# ESP32-S2 register map
Vendor: ESPRESSIF SYSTEMS (SHANGHAI) CO., LTD.; Series: ESP32 S-Series; File version: 20
CPU: Xtensa LX7 r0p0, little endian, no MPU, no FPU, 0 interrupt priority bits
Address unit: 32 bits
Registers are 32-bit, read-write, reset 0x0 unless marked. A register's access mark holds for its fields unless they carry their own. Offsets are from the block's base; [hi:lo] are bit positions.

## I2S0 — I2S (Inter-IC Sound) Controller 0
Base 0x3F40F000
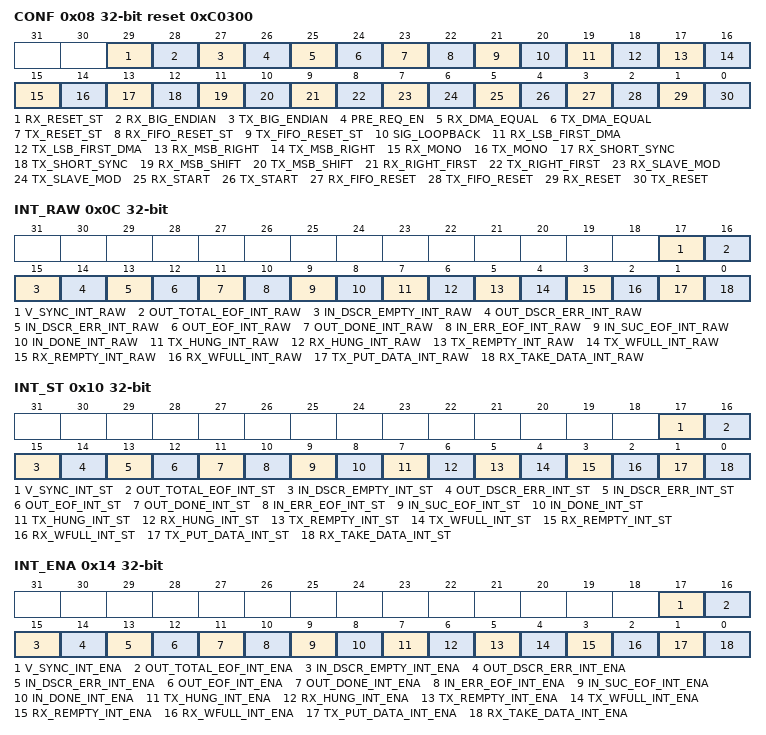
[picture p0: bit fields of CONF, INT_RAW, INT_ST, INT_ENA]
0x08 CONF access per field reset 0xC0300 — I2S configuration register
  [29] RX_RESET_ST ro — I2S RX reset status. 1: I2S_RX_RESET is not completed. 0: I2S_RX_RESET is completed.
  [28] RX_BIG_ENDIAN rw — I2S RX byte endianness.
  [27] TX_BIG_ENDIAN rw — I2S TX byte endianness.
  [26] PRE_REQ_EN rw — Set this bit to enable I2S to prepare data earlier.
  [25] RX_DMA_EQUAL rw — 1: Data in left channel is equal to data in right channel. 0: Data in left channel is not equal to data in right channel.
  [24] TX_DMA_EQUAL rw — 1: Data in left channel is equal to data in right channel. 0: Data in left channel is not equal to data in right channel.
  [23] TX_RESET_ST ro — I2S TX reset status. 1: I2S_TX_RESET is not completed. 0: I2S_TX_RESET is completed.
  [22] RX_FIFO_RESET_ST ro — I2S RX FIFO reset status. 1: I2S_RX_FIFO_RESET is not completed. 0: I2S_RX_FIFO_RESET is completed.
  [21] TX_FIFO_RESET_ST ro — I2S TX FIFO reset status. 1: I2S_TX_FIFO_RESET is not completed. 0: I2S_TX_FIFO_RESET is completed.
  [20] SIG_LOOPBACK rw — Enable signal loopback mode with transmitter module and receiver module sharing the same WS and BCK signals.
  [19] RX_LSB_FIRST_DMA rw — 1:the data in DMA/APB transform from low bits. 0:the data from DMA/APB transform from high bits.
  [18] TX_LSB_FIRST_DMA rw — 1:the data in DMA/APB transform from low bits. 0:the data from DMA/APB transform from high bits.
  [17] RX_MSB_RIGHT rw — Set this bit to place right channel data at the MSB in RX FIFO.
  [16] TX_MSB_RIGHT rw — Set this bit to place right channel data at the MSB in TX FIFO.
  [15] RX_MONO rw — Set this bit to enable receiver in mono mode.
  [14] TX_MONO rw — Set this bit to enable transmitter in mono mode.
  [13] RX_SHORT_SYNC rw — Set this bit to enable receiver in PCM standard mode.
  [12] TX_SHORT_SYNC rw — Set this bit to enable transmitter in PCM standard mode.
  [11] RX_MSB_SHIFT rw — Set this bit to enable receiver in Phillips standard mode.
  [10] TX_MSB_SHIFT rw — Set this bit to enable transmitter in Phillips standard mode.
  [9] RX_RIGHT_FIRST rw — Set this bit to receive right channel data first.
  [8] TX_RIGHT_FIRST rw — Set this bit to transmit right channel data first.
  [7] RX_SLAVE_MOD rw — Set this bit to enable slave receiver mode.
  [6] TX_SLAVE_MOD rw — Set this bit to enable slave transmitter mode.
  [5] RX_START rw — Set this bit to start receiving data.
  [4] TX_START rw — Set this bit to start transmitting data.
  [3] RX_FIFO_RESET wo — Set this bit to reset RX FIFO.
  [2] TX_FIFO_RESET wo — Set this bit to reset TX FIFO.
  [1] RX_RESET wo — Set this bit to reset receiver.
  [0] TX_RESET wo — Set this bit to reset transmitter.
0x0C INT_RAW ro — Raw interrupt status
  [17] V_SYNC_INT_RAW — The raw interrupt status bit for I2S_V_SYNC_INT interrupt.
  [16] OUT_TOTAL_EOF_INT_RAW — The raw interrupt status bit for I2S_OUT_TOTAL_EOF_INT interrupt.
  [15] IN_DSCR_EMPTY_INT_RAW — The raw interrupt status bit for I2S_IN_DSCR_EMPTY_INT interrupt.
  [14] OUT_DSCR_ERR_INT_RAW — The raw interrupt status bit for I2S_OUT_DSCR_ERR_INT interrupt.
  [13] IN_DSCR_ERR_INT_RAW — The raw interrupt status bit for I2S_IN_DSCR_ERR_INT interrupt.
  [12] OUT_EOF_INT_RAW — The raw interrupt status bit for I2S_OUT_EOF_INT interrupt.
  [11] OUT_DONE_INT_RAW — The raw interrupt status bit for I2S_OUT_DONE_INT interrupt.
  [10] IN_ERR_EOF_INT_RAW — Reserved.
  [9] IN_SUC_EOF_INT_RAW — The raw interrupt status bit for I2S_IN_SUC_EOF_INT interrupt.
  [8] IN_DONE_INT_RAW — The raw interrupt status bit for I2S_IN_DONE_INT interrupt.
  [7] TX_HUNG_INT_RAW — The raw interrupt status bit for I2S_TX_HUNG_INT interrupt.
  [6] RX_HUNG_INT_RAW — The raw interrupt status bit for I2S_RX_HUNG_INT interrupt.
  [5] TX_REMPTY_INT_RAW — The raw interrupt status bit for I2S_TX_REMPTY_INT interrupt.
  [4] TX_WFULL_INT_RAW — The raw interrupt status bit for I2S_TX_WFULL_INT interrupt.
  [3] RX_REMPTY_INT_RAW — The raw interrupt status bit for I2S_RX_REMPTY_INT interrupt.
  [2] RX_WFULL_INT_RAW — The raw interrupt status bit for I2S_RX_WFULL_INT interrupt.
  [1] TX_PUT_DATA_INT_RAW — The raw interrupt status bit for I2S_TX_PUT_DATA_INT interrupt.
  [0] RX_TAKE_DATA_INT_RAW — The raw interrupt status bit for I2S_RX_TAKE_DATA_INT interrupt.
0x10 INT_ST ro — Masked interrupt status
  [17] V_SYNC_INT_ST — The masked interrupt status bit for I2S_V_SYNC_INT interrupt.
  [16] OUT_TOTAL_EOF_INT_ST — The masked interrupt status bit for I2S_OUT_TOTAL_EOF_INT interrupt.
  [15] IN_DSCR_EMPTY_INT_ST — The masked interrupt status bit for I2S_IN_DSCR_EMPTY_INT interrupt.
  [14] OUT_DSCR_ERR_INT_ST — The masked interrupt status bit for I2S_OUT_DSCR_ERR_INT interrupt.
  [13] IN_DSCR_ERR_INT_ST — The masked interrupt status bit for I2S_IN_DSCR_ERR_INT interrupt.
  [12] OUT_EOF_INT_ST — The masked interrupt status bit for I2S_OUT_EOF_INT interrupt.
  [11] OUT_DONE_INT_ST — The masked interrupt status bit for I2S_OUT_DONE_INT interrupt.
  [10] IN_ERR_EOF_INT_ST — Reserved.
  [9] IN_SUC_EOF_INT_ST — The masked interrupt status bit for I2S_IN_SUC_EOF_INT interrupt.
  [8] IN_DONE_INT_ST — The masked interrupt status bit for I2S_IN_DONE_INT interrupt.
  [7] TX_HUNG_INT_ST — The masked interrupt status bit for I2S_TX_HUNG_INT interrupt.
  [6] RX_HUNG_INT_ST — The masked interrupt status bit for I2S_RX_HUNG_INT interrupt.
  [5] TX_REMPTY_INT_ST — The masked interrupt status bit for I2S_TX_REMPTY_INT interrupt.
  [4] TX_WFULL_INT_ST — The masked interrupt status bit for I2S_TX_WFULL_INT interrupt.
  [3] RX_REMPTY_INT_ST — The masked interrupt status bit for I2S_RX_REMPTY_INT interrupt.
  [2] RX_WFULL_INT_ST — The masked interrupt status bit for I2S_RX_WFULL_INT interrupt.
  [1] TX_PUT_DATA_INT_ST — The masked interrupt status bit for I2S_TX_PUT_DATA_INT interrupt.
  [0] RX_TAKE_DATA_INT_ST — The masked interrupt status bit for I2S_RX_TAKE_DATA_INT interrupt.
0x14 INT_ENA — Interrupt enable bits
  [17] V_SYNC_INT_ENA — The interrupt enable bit for I2S_V_SYNC_INT interrupt.
  [16] OUT_TOTAL_EOF_INT_ENA — The interrupt enable bit for I2S_OUT_TOTAL_EOF_INT interrupt.
  [15] IN_DSCR_EMPTY_INT_ENA — The interrupt enable bit for I2S_IN_DSCR_EMPTY_INT interrupt.
  [14] OUT_DSCR_ERR_INT_ENA — The interrupt enable bit for I2S_OUT_DSCR_ERR_INT interrupt.
  [13] IN_DSCR_ERR_INT_ENA — The interrupt enable bit for I2S_IN_DSCR_ERR_INT interrupt.
  [12] OUT_EOF_INT_ENA — The interrupt enable bit for I2S_OUT_EOF_INT interrupt.
  [11] OUT_DONE_INT_ENA — The interrupt enable bit for I2S_OUT_DONE_INT interrupt.
  [10] IN_ERR_EOF_INT_ENA — Reserved.
  [9] IN_SUC_EOF_INT_ENA — The interrupt enable bit for I2S_IN_SUC_EOF_INT interrupt.
  [8] IN_DONE_INT_ENA — The interrupt enable bit for I2S_IN_DONE_INT interrupt.
  [7] TX_HUNG_INT_ENA — The interrupt enable bit for I2S_TX_HUNG_INT interrupt.
  [6] RX_HUNG_INT_ENA — The interrupt enable bit for I2S_RX_HUNG_INT interrupt.
  [5] TX_REMPTY_INT_ENA — The interrupt enable bit for I2S_TX_REMPTY_INT interrupt.
  [4] TX_WFULL_INT_ENA — The interrupt enable bit for I2S_TX_WFULL_INT interrupt.
  [3] RX_REMPTY_INT_ENA — The interrupt enable bit for I2S_RX_REMPTY_INT interrupt.
  [2] RX_WFULL_INT_ENA — The interrupt enable bit for I2S_RX_WFULL_INT interrupt.
  [1] TX_PUT_DATA_INT_ENA — The interrupt enable bit for I2S_TX_PUT_DATA_INT interrupt.
  [0] RX_TAKE_DATA_INT_ENA — The interrupt enable bit for I2S_RX_TAKE_DATA_INT interrupt.
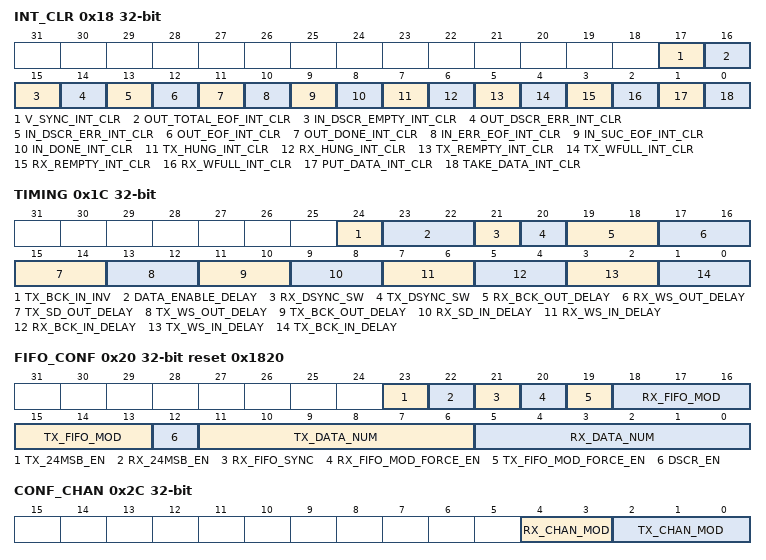
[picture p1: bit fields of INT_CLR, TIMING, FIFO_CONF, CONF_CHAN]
0x18 INT_CLR wo — Interrupt clear bits
  [17] V_SYNC_INT_CLR — Set this bit to clear I2S_V_SYNC_INT interrupt.
  [16] OUT_TOTAL_EOF_INT_CLR — Set this bit to clear I2S_OUT_TOTAL_EOF_INT interrupt.
  [15] IN_DSCR_EMPTY_INT_CLR — Set this bit to clear I2S_IN_DSCR_EMPTY_INT interrupt.
  [14] OUT_DSCR_ERR_INT_CLR — Set this bit to clear I2S_OUT_DSCR_ERR_INT interrupt.
  [13] IN_DSCR_ERR_INT_CLR — Set this bit to clear I2S_IN_DSCR_ERR_INT interrupt.
  [12] OUT_EOF_INT_CLR — Set this bit to clear I2S_OUT_EOF_INT interrupt.
  [11] OUT_DONE_INT_CLR — Set this bit to clear I2S_OUT_DONE_INT interrupt.
  [10] IN_ERR_EOF_INT_CLR — Reserved.
  [9] IN_SUC_EOF_INT_CLR — Set this bit to clear I2S_IN_SUC_EOF_INT interrupt.
  [8] IN_DONE_INT_CLR — Set this bit to clear I2S_IN_DONE_INT interrupt.
  [7] TX_HUNG_INT_CLR — Set this bit to clear I2S_TX_HUNG_INT interrupt.
  [6] RX_HUNG_INT_CLR — Set this bit to clear I2S_RX_HUNG_INT interrupt.
  [5] TX_REMPTY_INT_CLR — Set this bit to clear I2S_TX_REMPTY_INT interrupt.
  [4] TX_WFULL_INT_CLR — Set this bit to clear I2S_TX_WFULL_INT interrupt.
  [3] RX_REMPTY_INT_CLR — Set this bit to clear I2S_RX_REMPTY_INT interrupt.
  [2] RX_WFULL_INT_CLR — Set this bit to clear I2S_RX_WFULL_INT interrupt.
  [1] PUT_DATA_INT_CLR — Set this bit to clear I2S_TX_PUT_DATA_INT interrupt.
  [0] TAKE_DATA_INT_CLR — Set this bit to clear I2S_RX_TAKE_DATA_INT interrupt.
0x1C TIMING — I2S timing register
  [24] TX_BCK_IN_INV — Set this bit to invert BCK signal input to the slave transmitter.
  [23:22] DATA_ENABLE_DELAY — Number of delay cycles for data valid flag based on I2S0_CLK. 0: delayed by 1.5 cycles. 1: delayed by 2.5 cycles. 2: delayed by 3.5 cycles. 3: delayed by 4.5 cycles.
  [21] RX_DSYNC_SW — Set this bit to synchronize signals into the receiver by two flip-flop synchronizer. 0: the signals will be clocked by rising clock edge firstly, then clocked by falling clock edge. 1: the signals will be clocked by falling clock edge firstly, then clocked by rising clock edge.
  [20] TX_DSYNC_SW — Set this bit to synchronize signals into the transmitter by two flip-flop synchronizer. 0: the signals will be firstly clocked by rising clock edge , then clocked by falling clock edge. 1: the signals will be firstly clocked by falling clock edge, then clocked by rising clock edge.
  [19:18] RX_BCK_OUT_DELAY — Number of delay cycles for BCK signal out of the receiver based on I2S0_CLK. 0: delayed by 0 cycle. 1: delayed by 1 cycle. 2: delayed by 2 cycles. 3: delayed by 3 cycles.
  [17:16] RX_WS_OUT_DELAY — Number of delay cycles for WS signal out of the receiver based on I2S0_CLK. 0: delayed by 0 cycle. 1: delayed by 1 cycle. 2: delayed by 2 cycles. 3: delayed by 3 cycles.
  [15:14] TX_SD_OUT_DELAY — Number of delay cycles for SD signal out of the transmitter based on I2S0_CLK. 0: delayed by 0 cycle. 1: delayed by 1 cycle. 2: delayed by 2 cycles. 3: delayed by 3 cycles.
  [13:12] TX_WS_OUT_DELAY — Number of delay cycles for WS signal out of the transmitter based on I2S0_CLK. 0: delayed by 0 cycle. 1: delayed by 1 cycle. 2: delayed by 2 cycles. 3: delayed by 3 cycles.
  [11:10] TX_BCK_OUT_DELAY — Number of delay cycles for BCK signal out of the transmitter based on I2S0_CLK. 0: delayed by 0 cycle. 1: delayed by 1 cycle. 2: delayed by 2 cycles. 3: delayed by 3 cycles.
  [9:8] RX_SD_IN_DELAY — Number of delay cycles for SD signal into the receiver based on I2S0_CLK. 0: delayed by 1.5 cycles. 1: delayed by 2.5 cycles. 2: delayed by 3.5 cycles. 3: delayed by 4.5 cycles.
  [7:6] RX_WS_IN_DELAY — Number of delay cycles for WS signal into the receiver based on I2S0_CLK. 0: delayed by 1.5 cycles. 1: delayed by 2.5 cycles. 2: delayed by 3.5 cycles. 3: delayed by 4.5 cycles.
  [5:4] RX_BCK_IN_DELAY — Number of delay cycles for BCK signal into the receiver based on I2S0_CLK. 0: delayed by 1.5 cycles. 1: delayed by 2.5 cycles. 2: delayed by 3.5 cycles. 3: delayed by 4.5 cycles.
  [3:2] TX_WS_IN_DELAY — Number of delay cycles for WS signal into the transmitter based on I2S0_CLK. 0: delayed by 1.5 cycles. 1: delayed by 2.5 cycles. 2: delayed by 3.5 cycles. 3: delayed by 4.5 cycles.
  [1:0] TX_BCK_IN_DELAY — Number of delay cycles for BCK signal into the transmitter based on I2S0_CLK. 0: delayed by 1.5 cycles. 1: delayed by 2.5 cycles. 2: delayed by 3.5 cycles. 3: delayed by 4.5 cycles.
0x20 FIFO_CONF reset 0x1820 — I2S FIFO configuration register
  [23] TX_24MSB_EN — Only useful in tx 24bit mode. 1: the high 24 bits are effective in i2s fifo 0: the low 24 bits are effective in i2s fifo
  [22] RX_24MSB_EN — Only useful in rx 24bit mode. 1: the high 24 bits are effective in i2s fifo 0: the low 24 bits are effective in i2s fifo
  [21] RX_FIFO_SYNC — force write back rx data to memory
  [20] RX_FIFO_MOD_FORCE_EN — The bit should always be set to 1
  [19] TX_FIFO_MOD_FORCE_EN — The bit should always be set to 1
  [18:16] RX_FIFO_MOD — Receiver FIFO mode configuration bits
  [15:13] TX_FIFO_MOD — Transmitter FIFO mode configuration bits
  [12] DSCR_EN — Set this bit to enable I2S DMA mode.
  [11:6] TX_DATA_NUM — I2S_TX_PUT_DATA_INT is triggered when the left and right channel data number in TX FIFO is smaller than the value of I2S_TX_DATA_NUM[5:0]. (TX FIFO is almost empty threshold.)
  [5:0] RX_DATA_NUM — I2S_RX_TAKE_DATA_INT is triggered when the left and right channel data number in RX FIFO is larger than the value of I2S_RX_DATA_NUM[5:0]. (RX FIFO is almost full threshold.)
0x24 RXEOF_NUM reset 0x40 — I2S DMA RX EOF data length
  [31:0] RX_EOF_NUM — The length of data to be received. It will trigger I2S_IN_SUC_EOF_INT.
0x28 CONF_SIGLE_DATA — Constant single channel data
  [31:0] SIGLE_DATA — The right channel or left channel transmits constant value stored in this register according to I2S_TX_CHAN_MOD and I2S_TX_MSB_RIGHT.
0x2C CONF_CHAN — I2S channel configuration register
  [4:3] RX_CHAN_MOD — I2S receiver channel mode configuration bits.
  [2:0] TX_CHAN_MOD — I2S transmitter channel mode configuration bits.
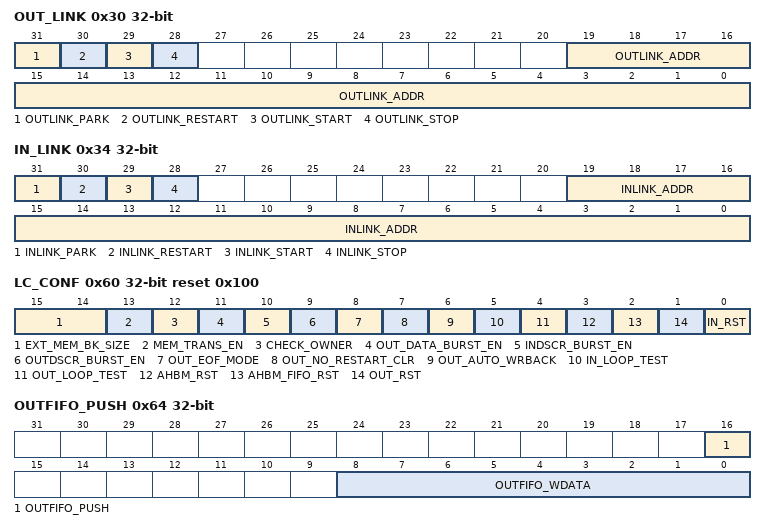
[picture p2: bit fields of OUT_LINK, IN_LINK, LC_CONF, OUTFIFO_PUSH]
0x30 OUT_LINK access per field — I2S DMA TX configuration register
  [31] OUTLINK_PARK ro
  [30] OUTLINK_RESTART rw — Set this bit to restart outlink descriptor.
  [29] OUTLINK_START rw — Set this bit to start outlink descriptor.
  [28] OUTLINK_STOP rw — Set this bit to stop outlink descriptor.
  [19:0] OUTLINK_ADDR rw — The address of first outlink descriptor.
0x34 IN_LINK access per field — I2S DMA RX configuration register
  [31] INLINK_PARK ro
  [30] INLINK_RESTART rw — Set this bit to restart inlink descriptor.
  [29] INLINK_START rw — Set this bit to start inlink descriptor.
  [28] INLINK_STOP rw — Set this bit to stop inlink descriptor.
  [19:0] INLINK_ADDR rw — The address of first inlink descriptor.
0x38 OUT_EOF_DES_ADDR ro — Address of outlink descriptor that produces EOF
  [31:0] OUT_EOF_DES_ADDR — The address of outlink descriptor that produces EOF.
0x3C IN_EOF_DES_ADDR ro — Address of inlink descriptor that produces EOF
  [31:0] IN_SUC_EOF_DES_ADDR — The address of inlink descriptor that produces EOF.
0x40 OUT_EOF_BFR_DES_ADDR ro — Address of buffer relative to the outlink descriptor that produces EOF
  [31:0] OUT_EOF_BFR_DES_ADDR — The address of buffer relative to the outlink descriptor that produces EOF.
0x48 INLINK_DSCR ro — Address of current inlink descriptor
  [31:0] INLINK_DSCR — The address of current inlink descriptor.
0x4C INLINK_DSCR_BF0 ro — Address of next inlink descriptor
  [31:0] INLINK_DSCR_BF0 — The address of next inlink descriptor.
0x50 INLINK_DSCR_BF1 ro — Address of next inlink data buffer
  [31:0] INLINK_DSCR_BF1 — The address of next inlink data buffer.
0x54 OUTLINK_DSCR ro — Address of current outlink descriptor
  [31:0] OUTLINK_DSCR — The address of current outlink descriptor.
0x58 OUTLINK_DSCR_BF0 ro — Address of next outlink descriptor
  [31:0] OUTLINK_DSCR_BF0 — The address of next outlink descriptor.
0x5C OUTLINK_DSCR_BF1 ro — Address of next outlink data buffer
  [31:0] OUTLINK_DSCR_BF1 — The address of next outlink data buffer.
0x60 LC_CONF reset 0x100 — I2S DMA configuration register
  [15:14] EXT_MEM_BK_SIZE — DMA access external memory block size. 0: 16 bytes. 1: 32 bytes. 2: 64 bytes. 3: reserved.
  [13] MEM_TRANS_EN — Reserved.
  [12] CHECK_OWNER — Set this bit to enable check owner bit by hardware.
  [11] OUT_DATA_BURST_EN — Transmitter data transfer mode configuration bit. 1: Prepare out data with burst mode. 0: Prepare out data with byte mode.
  [10] INDSCR_BURST_EN — DMA inlink descriptor transfer mode configuration bit. 1: Prepare inlink descriptor with burst mode. 0: Prepare inlink descriptor with byte mode.
  [9] OUTDSCR_BURST_EN — DMA outlink descriptor transfer mode configuration bit. 1: Prepare outlink descriptor with burst mode. 0: Prepare outlink descriptor with byte mode.
  [8] OUT_EOF_MODE — DMA out EOF flag generation mode. 1: When DMA has popped all data from the FIFO. 0: When AHB has pushed all data to the FIFO.
  [7] OUT_NO_RESTART_CLR — Reserved.
  [6] OUT_AUTO_WRBACK — Set this bit to enable outlink-written-back automatically when out buffer is transmitted done.
  [5] IN_LOOP_TEST — Set this bit to loop test outlink.
  [4] OUT_LOOP_TEST — Set this bit to loop test inlink.
  [3] AHBM_RST — Set this bit to reset AHB interface of DMA. Set this bit before the DMA configuration.
  [2] AHBM_FIFO_RST — Set this bit to reset AHB interface cmdFIFO of DMA. Set this bit before the DMA configuration.
  [1] OUT_RST — Set this bit to reset out-DMA FSM. Set this bit before the DMA configuration.
  [0] IN_RST — Set this bit to reset in-DMA FSM. Set this bit before the DMA configuration.
0x64 OUTFIFO_PUSH — APB out FIFO mode register
  [16] OUTFIFO_PUSH — APB out FIFO push.
  [8:0] OUTFIFO_WDATA — APB out FIFO write data.
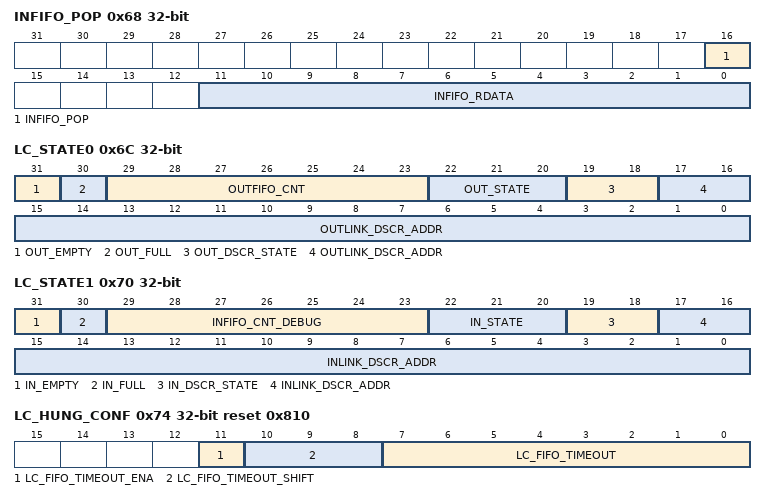
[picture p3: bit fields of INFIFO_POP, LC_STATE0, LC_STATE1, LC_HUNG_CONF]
0x68 INFIFO_POP access per field — APB in FIFO mode register
  [16] INFIFO_POP rw — APB in FIFO pop.
  [11:0] INFIFO_RDATA ro — APB in FIFO read data.
0x6C LC_STATE0 ro — I2S DMA TX status
  [31] OUT_EMPTY — I2S DMA outfifo is empty.
  [30] OUT_FULL — I2S DMA outfifo is full.
  [29:23] OUTFIFO_CNT — The remains of I2S DMA outfifo data.
  [22:20] OUT_STATE — I2S DMA out data state.
  [19:18] OUT_DSCR_STATE — I2S DMA out descriptor state.
  [17:0] OUTLINK_DSCR_ADDR — I2S DMA out descriptor address.
0x70 LC_STATE1 ro — I2S DMA RX status
  [31] IN_EMPTY — I2S DMA infifo is empty.
  [30] IN_FULL — I2S DMA infifo is full.
  [29:23] INFIFO_CNT_DEBUG — The remains of I2S DMA infifo data.
  [22:20] IN_STATE — I2S DMA in data state.
  [19:18] IN_DSCR_STATE — I2S DMA in descriptor state.
  [17:0] INLINK_DSCR_ADDR — I2S DMA in descriptor address.
0x74 LC_HUNG_CONF reset 0x810 — I2S Hung configuration register
  [11] LC_FIFO_TIMEOUT_ENA — The enable bit for FIFO timeout.
  [10:8] LC_FIFO_TIMEOUT_SHIFT — The bits are used to set the tick counter threshold. The tick counter is clocked by APB_CLK. The tick counter threshold is 88000/2^I2S_LC_FIFO_TIMEOUT_SHIFT. The tick counter is reset when it reaches the threshold.
  [7:0] LC_FIFO_TIMEOUT — I2S_TX_HUNG_INT interrupt or I2S_RX_HUNG_INT interrupt will be triggered when FIFO hung counter is equal to this value.
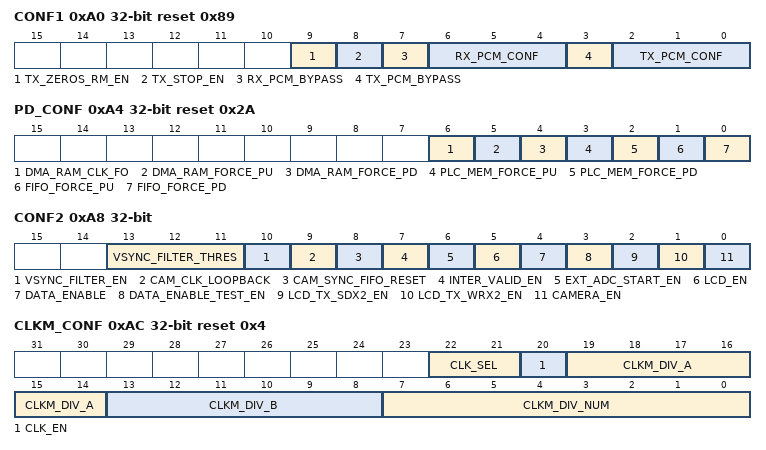
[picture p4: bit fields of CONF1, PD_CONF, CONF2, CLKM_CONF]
0xA0 CONF1 reset 0x89 — I2S configuration register 1
  [9] TX_ZEROS_RM_EN — Reserved.
  [8] TX_STOP_EN — Set this bit to stop the output of BCK signal and WS signal when TX FIFO is empty.
  [7] RX_PCM_BYPASS — Set this bit to bypass Compress/Decompress module for received data.
  [6:4] RX_PCM_CONF — Compress/Decompress module configuration bits. 0: decompress received data 1:compress received data
  [3] TX_PCM_BYPASS — Set this bit to bypass Compress/Decompress module for transmitted data.
  [2:0] TX_PCM_CONF — Compress/Decompress module configuration bits. 0: decompress transmitted data 1:compress transmitted data
0xA4 PD_CONF reset 0x2A — I2S power-down configuration register
  [6] DMA_RAM_CLK_FO — Set this bit to force on DMA RAM clock.
  [5] DMA_RAM_FORCE_PU — Force DMA FIFO power-up.
  [4] DMA_RAM_FORCE_PD — Force DMA FIFO power-down.
  [3] PLC_MEM_FORCE_PU — Force I2S memory power-up.
  [2] PLC_MEM_FORCE_PD — Force I2S memory power-down.
  [1] FIFO_FORCE_PU — Force FIFO power-up.
  [0] FIFO_FORCE_PD — Force FIFO power-down.
0xA8 CONF2 — I2S configuration register 2
  [13:11] VSYNC_FILTER_THRES — Configure the I2S VSYNC filter threshold value.
  [10] VSYNC_FILTER_EN — Set this bit to enable I2S VSYNC filter function.
  [9] CAM_CLK_LOOPBACK — Set this bit to loopback PCLK from I2S0I_WS_out.
  [8] CAM_SYNC_FIFO_RESET — Set this bit to reset FIFO in camera mode.
  [7] INTER_VALID_EN — Set this bit to enable camera VGA reducing-resolution mode: only receive two consecutive cycle data in four consecutive clocks.
  [6] EXT_ADC_START_EN — Set this bit to enable the function that ADC mode is triggered by external signal.
  [5] LCD_EN — Set this bit to enable LCD mode.
  [4] DATA_ENABLE — for debug camera mode enable
  [3] DATA_ENABLE_TEST_EN — for debug camera mode enable
  [2] LCD_TX_SDX2_EN — Set this bit to duplicate data pairs (Frame Form 2) in LCD mode.
  [1] LCD_TX_WRX2_EN — LCD WR double for one datum.
  [0] CAMERA_EN — Set this bit to enable camera mode.
0xAC CLKM_CONF reset 0x4 — I2S module clock configuration register
  [22:21] CLK_SEL — Set this bit to select I2S module clock source. 0: No clock. 1: APLL_CLK. 2: PLL_160M_CLK. 3: No clock.
  [20] CLK_EN — Set this bit to enable clock gate.
  [19:14] CLKM_DIV_A — Fractional clock divider denominator value.
  [13:8] CLKM_DIV_B — Fractional clock divider numerator value.
  [7:0] CLKM_DIV_NUM — Integral I2S clock divider value.
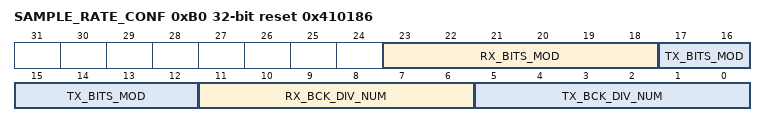
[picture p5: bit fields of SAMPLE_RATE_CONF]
0xB0 SAMPLE_RATE_CONF reset 0x410186 — I2S sample rate register
  [23:18] RX_BITS_MOD — Set the bits to configure bit length of I2S receiver channel, the value of which can only be 8, 16, 24 and 32.
  [17:12] TX_BITS_MOD — Set the bits to configure bit length of I2S transmitter channel, the value of which can only be 8, 16, 24 and 32.
  [11:6] RX_BCK_DIV_NUM — Bit clock configuration bits in receiver mode.
  [5:0] TX_BCK_DIV_NUM — Bit clock configuration bits in transmitter mode.
0xBC STATE ro reset 0x1 — I2S TX status register
  [0] TX_IDLE — 1: I2S TX is in idle state. 0: I2S TX is at work.
0xFC DATE reset 0x19052500 — Version control register
